VERSION ""

NS_ :

BS_:

BU_: Ibeo_Vehicle_and_Object_data

BO_ 1032 LUX_ObjectDataListTailer: 2 Vector__XXX
 SG_ NumberOfObjectSent : 7|16@0+ (1,0) [0|0] "" Vector__XXX

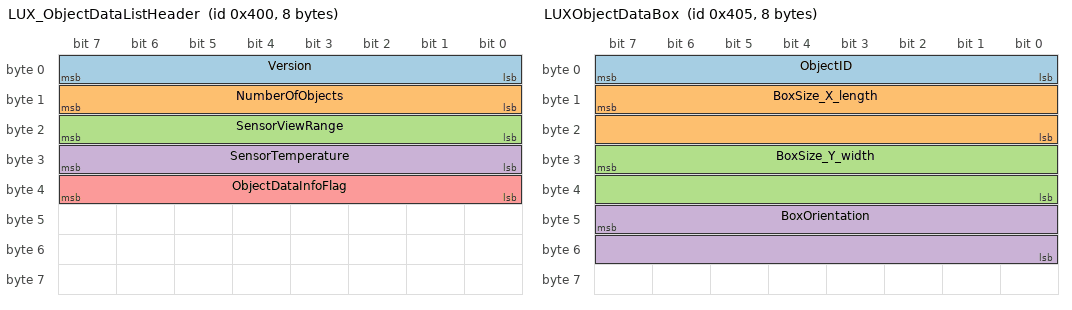
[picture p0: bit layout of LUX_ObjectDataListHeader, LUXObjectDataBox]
BO_ 1024 LUX_ObjectDataListHeader: 8 Ibeo_Vehicle_and_Object_data
 SG_ Version : 7|8@0+ (1,0) [0|255] ""  Ibeo_Vehicle_and_Object_data
 SG_ NumberOfObjects : 15|8@0+ (1,0) [0|255] ""  Ibeo_Vehicle_and_Object_data
 SG_ SensorViewRange : 23|8@0+ (1,0) [0|255] ""  Ibeo_Vehicle_and_Object_data
 SG_ SensorTemperature : 31|8@0- (1,0) [-128|127] ""  Ibeo_Vehicle_and_Object_data
 SG_ ObjectDataInfoFlag : 39|8@0- (1,0) [0|255] ""  Ibeo_Vehicle_and_Object_data

BO_ 1029 LUXObjectDataBox: 8 Ibeo_Vehicle_and_Object_data
 SG_ ObjectID : 7|8@0+ (1,0) [0|255] ""  Ibeo_Vehicle_and_Object_data
 SG_ BoxSize_X_length : 15|16@0+ (1,0) [0|65535] "cm"  Ibeo_Vehicle_and_Object_data
 SG_ BoxSize_Y_width : 31|16@0+ (1,0) [0|65535] "cm"  Ibeo_Vehicle_and_Object_data
 SG_ BoxOrientation : 47|16@0- (0.01,0) [-327.68|327.67] "�"  Ibeo_Vehicle_and_Object_data

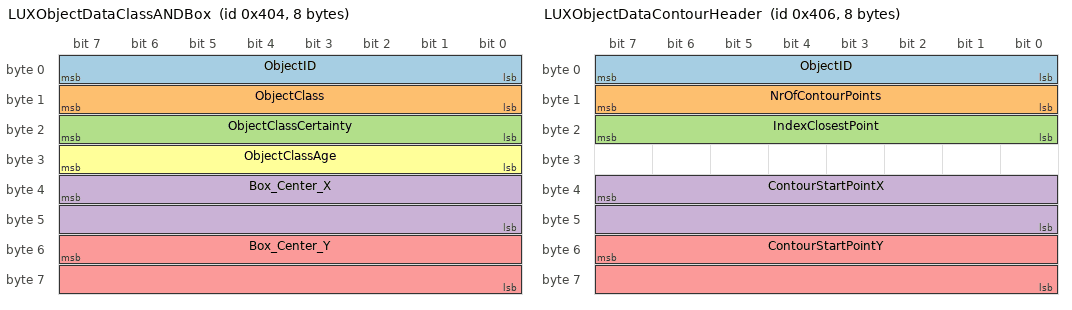
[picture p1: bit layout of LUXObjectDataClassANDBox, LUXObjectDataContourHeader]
BO_ 1028 LUXObjectDataClassANDBox: 8 Ibeo_Vehicle_and_Object_data
 SG_ ObjectID : 7|8@0+ (1,0) [0|255] ""  Ibeo_Vehicle_and_Object_data
 SG_ ObjectClass : 15|8@0- (1,0) [0|255] ""  Ibeo_Vehicle_and_Object_data
 SG_ ObjectClassCertainty : 23|8@0+ (1,0) [0|255] "%"  Ibeo_Vehicle_and_Object_data
 SG_ Box_Center_X : 39|16@0- (1,0) [-32768|32767] "cm"  Ibeo_Vehicle_and_Object_data
 SG_ Box_Center_Y : 55|16@0- (1,0) [-32768|32767] "cm"  Ibeo_Vehicle_and_Object_data
 SG_ ObjectClassAge : 31|8@0+ (1,0) [0|255] "scans"  Ibeo_Vehicle_and_Object_data

BO_ 1030 LUXObjectDataContourHeader: 8 Ibeo_Vehicle_and_Object_data
 SG_ ObjectID : 7|8@0+ (1,0) [0|255] ""  Ibeo_Vehicle_and_Object_data
 SG_ NrOfContourPoints : 15|8@0+ (1,0) [0|255] ""  Ibeo_Vehicle_and_Object_data
 SG_ IndexClosestPoint : 23|8@0+ (1,0) [0|255] ""  Ibeo_Vehicle_and_Object_data
 SG_ ContourStartPointX : 39|16@0- (1,0) [-32768|32767] "cm"  Ibeo_Vehicle_and_Object_data
 SG_ ContourStartPointY : 55|16@0- (1,0) [-32768|32767] "cm"  Ibeo_Vehicle_and_Object_data

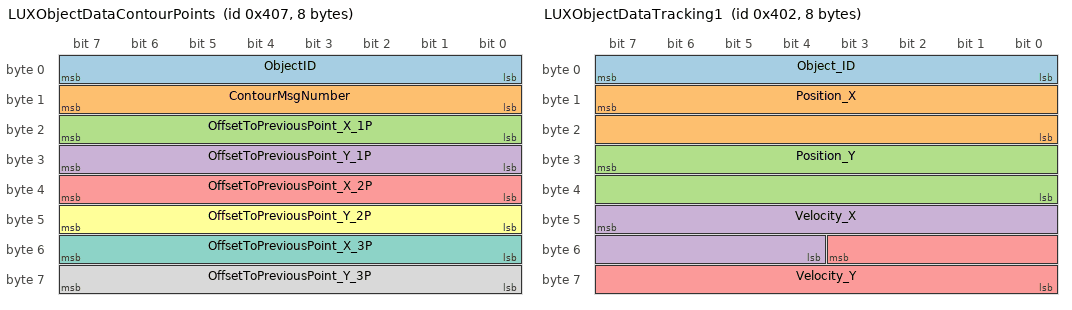
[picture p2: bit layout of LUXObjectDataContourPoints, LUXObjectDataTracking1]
BO_ 1031 LUXObjectDataContourPoints: 8 Ibeo_Vehicle_and_Object_data
 SG_ ObjectID : 7|8@0+ (1,0) [0|255] ""  Ibeo_Vehicle_and_Object_data
 SG_ ContourMsgNumber : 15|8@0+ (1,0) [0|255] ""  Ibeo_Vehicle_and_Object_data
 SG_ OffsetToPreviousPoint_X_1P : 23|8@0- (4,0) [-512|508] "cm"  Ibeo_Vehicle_and_Object_data
 SG_ OffsetToPreviousPoint_Y_1P : 31|8@0- (4,0) [-512|508] "cm"  Ibeo_Vehicle_and_Object_data
 SG_ OffsetToPreviousPoint_X_2P : 39|8@0- (4,0) [-512|508] "cm"  Ibeo_Vehicle_and_Object_data
 SG_ OffsetToPreviousPoint_Y_2P : 47|8@0- (4,0) [-512|508] "cm"  Ibeo_Vehicle_and_Object_data
 SG_ OffsetToPreviousPoint_X_3P : 55|8@0- (4,0) [-512|508] "cm"  Ibeo_Vehicle_and_Object_data
 SG_ OffsetToPreviousPoint_Y_3P : 63|8@0- (4,0) [-512|508] "cm"  Ibeo_Vehicle_and_Object_data

BO_ 1026 LUXObjectDataTracking1: 8 Ibeo_Vehicle_and_Object_data
 SG_ Object_ID : 7|8@0+ (1,0) [0|255] ""  Ibeo_Vehicle_and_Object_data
 SG_ Position_X : 15|16@0- (1,0) [-32768|32767] "cm"  Ibeo_Vehicle_and_Object_data
 SG_ Position_Y : 31|16@0- (1,0) [-32768|32767] "cm"  Ibeo_Vehicle_and_Object_data
 SG_ Velocity_X : 47|12@0- (0.1,0) [-204.8|204.7] "m/s"  Ibeo_Vehicle_and_Object_data
 SG_ Velocity_Y : 51|12@0- (0.1,0) [-204.8|204.7] "m/s"  Ibeo_Vehicle_and_Object_data

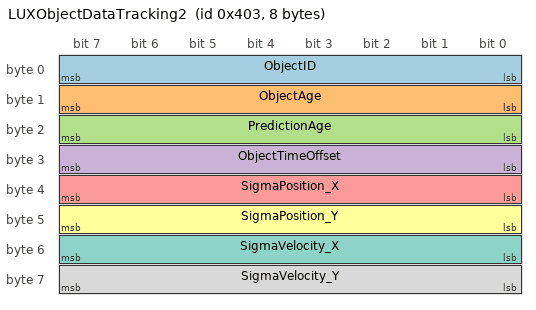
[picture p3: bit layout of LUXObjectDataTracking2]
BO_ 1027 LUXObjectDataTracking2: 8 Ibeo_Vehicle_and_Object_data
 SG_ ObjectID : 7|8@0+ (1,0) [0|255] ""  Ibeo_Vehicle_and_Object_data
 SG_ ObjectAge : 15|8@0+ (1,0) [0|255] "scans"  Ibeo_Vehicle_and_Object_data
 SG_ PredictionAge : 23|8@0+ (1,0) [0|255] "scans"  Ibeo_Vehicle_and_Object_data
 SG_ ObjectTimeOffset : 31|8@0+ (1,0) [0|255] "ms"  Ibeo_Vehicle_and_Object_data
 SG_ SigmaPosition_X : 39|8@0+ (1,0) [0|255] "cm"  Ibeo_Vehicle_and_Object_data
 SG_ SigmaPosition_Y : 47|8@0+ (1,0) [0|255] "cm"  Ibeo_Vehicle_and_Object_data
 SG_ SigmaVelocity_X : 55|8@0+ (0.1,0) [0|25.5] "m/s"  Ibeo_Vehicle_and_Object_data
 SG_ SigmaVelocity_Y : 63|8@0+ (0.1,0) [0|25.5] "m/s"  Ibeo_Vehicle_and_Object_data

BO_ 1025 LUXTime: 8 Ibeo_Vehicle_and_Object_data
 SG_ NTP_Seconds : 7|32@0+ (1,0) [0|4294967295] "s"  Ibeo_Vehicle_and_Object_data
 SG_ NTP_fractSeconds : 39|32@0+ (1,0) [0|4294967295] "(1/2^32)s"  Ibeo_Vehicle_and_Object_data

BO_ 772 VehicleCrossAcceleration: 8 Ibeo_Vehicle_and_Object_data
 SG_ ProtocolVersion : 7|8@0+ (1,0) [0|255] ""  Ibeo_Vehicle_and_Object_data
 SG_ CrossAcceleration : 15|16@0- (0.01,0) [-327.68|327.67] "m/s^2"  Ibeo_Vehicle_and_Object_data

BO_ 773 VehicleSteeeringWheelAngle: 8 Ibeo_Vehicle_and_Object_data
 SG_ ProtocolVersion : 7|8@0+ (1,0) [0|255] ""  Ibeo_Vehicle_and_Object_data
 SG_ SteeringWheelAngle : 15|16@0- (0.001,0) [-32.768|32.767] "rad"  Ibeo_Vehicle_and_Object_data

BO_ 771 VehicleVelocity: 8 Ibeo_Vehicle_and_Object_data
 SG_ ProtocolVersion : 7|8@0+ (1,0) [0|255] ""  Ibeo_Vehicle_and_Object_data
 SG_ Velocity : 15|16@0- (0.01,0) [-327.68|327.67] "m/s"  Ibeo_Vehicle_and_Object_data

BO_ 774 VehicleYawRate: 8 Ibeo_Vehicle_and_Object_data
 SG_ ProtocolVersion : 7|8@0+ (1,0) [0|255] ""  Ibeo_Vehicle_and_Object_data
 SG_ YawRate : 15|16@0- (0.0001,0) [-3.2768|3.2767] "rad/s"  Ibeo_Vehicle_and_Object_data

VAL_ 1024 ObjectDataInfoFlag 0 "Velocity = absolute, Boxes= Object Boxes" 1 "Velocity = relative, Boxes = Object Boxes" 2 "Velocity = absolute, Boxes = Bounding Boxes" 3 "Velocity = relative, Boxes = Bounding Boxes" ;
VAL_ 1028 ObjectClass 0 "unclassified" 1 "unknown small" 2 "unknown big" 3 "pedestrian" 4 "bike" 5 "car" 6 "truck" ;
VAL_ 1027 ObjectTimeOffset 0 "Object initialized (new Object)" 1 "Object predicted/associated" ;
VAL_ 772 CrossAcceleration 32768 "Invalid" ;
VAL_ 773 SteeringWheelAngle 32768 "Invalid" ;
VAL_ 771 Velocity 32768 "Invalid" ;
VAL_ 774 YawRate 32768 "Invalid" ;
